VERSION "MUR_Dash_CAN_v1.0"

NS_ :

BS_:

BU_: DASH SCREEN

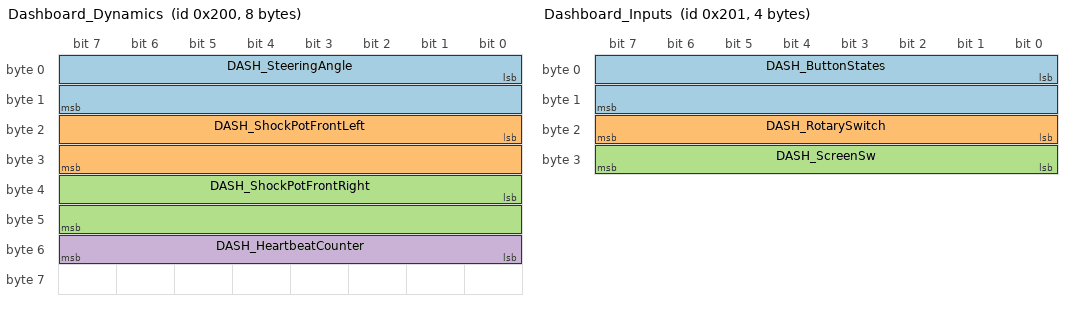
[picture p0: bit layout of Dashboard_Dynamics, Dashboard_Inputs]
BO_ 512 Dashboard_Dynamics: 8 DASH
 SG_ DASH_SteeringAngle : 0|16@1- (0.1,0) [-1800|1800] "deg" SCREEN
 SG_ DASH_ShockPotFrontLeft : 16|16@1+ (0.1,0) [0|500] "mm" SCREEN
 SG_ DASH_ShockPotFrontRight : 32|16@1+ (0.1,0) [0|500] "mm" SCREEN
 SG_ DASH_HeartbeatCounter : 48|8@1+ (1,0) [0|255] "" SCREEN

BO_ 513 Dashboard_Inputs: 4 DASH
 SG_ DASH_ButtonStates : 0|16@1+ (1,0) [0|65535] "" SCREEN
 SG_ DASH_RotarySwitch : 16|8@1+ (1,0) [0|15] "" SCREEN
 SG_ DASH_ScreenSw : 24|8@1+ (1,0) [0|255] "" SCREEN

BO_ 514 Dashboard_Environment: 4 DASH
 SG_ DASH_WindSpeed : 0|16@1+ (0.1,0) [0|6553.5] "m/s" SCREEN

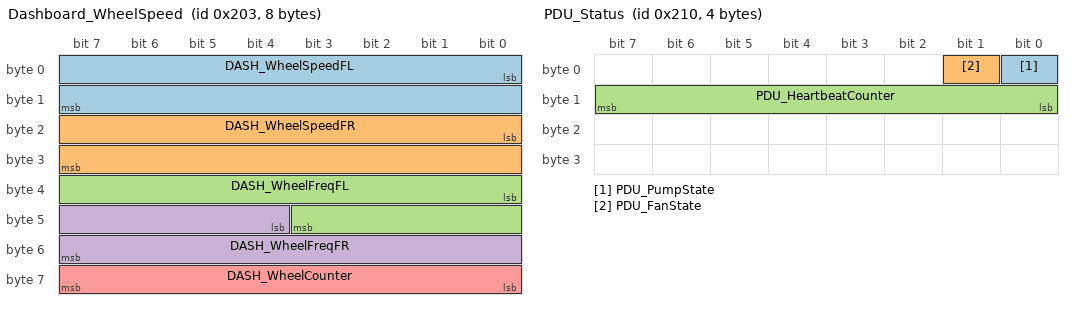
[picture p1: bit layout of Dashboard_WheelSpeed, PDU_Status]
BO_ 515 Dashboard_WheelSpeed: 8 DASH
 SG_ DASH_WheelSpeedFL : 0|16@1+ (0.1,0) [0|6553.4] "rpm" SCREEN
 SG_ DASH_WheelSpeedFR : 16|16@1+ (0.1,0) [0|6553.4] "rpm" SCREEN
 SG_ DASH_WheelFreqFL : 32|12@1+ (1,0) [0|4095] "Hz" SCREEN
 SG_ DASH_WheelFreqFR : 44|12@1+ (1,0) [0|4095] "Hz" SCREEN
 SG_ DASH_WheelCounter : 56|8@1+ (1,0) [0|255] "" SCREEN

BO_ 528 PDU_Status: 4 DASH
 SG_ PDU_PumpState : 0|1@1+ (1,0) [0|1] "" SCREEN
 SG_ PDU_FanState : 1|1@1+ (1,0) [0|1] "" SCREEN
 SG_ PDU_HeartbeatCounter : 8|8@1+ (1,0) [0|255] "" SCREEN

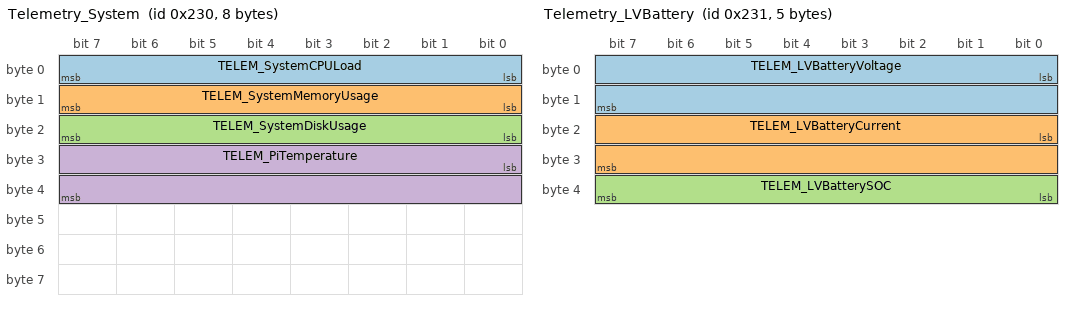
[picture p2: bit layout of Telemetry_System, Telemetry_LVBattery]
BO_ 560 Telemetry_System: 8 DASH
 SG_ TELEM_SystemCPULoad : 0|8@1+ (1,0) [0|100] "%" SCREEN
 SG_ TELEM_SystemMemoryUsage : 8|8@1+ (1,0) [0|100] "%" SCREEN
 SG_ TELEM_SystemDiskUsage : 16|8@1+ (1,0) [0|100] "%" SCREEN
 SG_ TELEM_PiTemperature : 24|16@1- (0.1,0) [-3276.8|3276.7] "degC" SCREEN

BO_ 561 Telemetry_LVBattery: 5 DASH
 SG_ TELEM_LVBatteryVoltage : 0|16@1+ (0.01,0) [0|655.35] "V" SCREEN
 SG_ TELEM_LVBatteryCurrent : 16|16@1- (0.1,0) [-3276.8|3276.7] "A" SCREEN
 SG_ TELEM_LVBatterySOC : 32|8@1+ (1,0) [0|100] "%" SCREEN

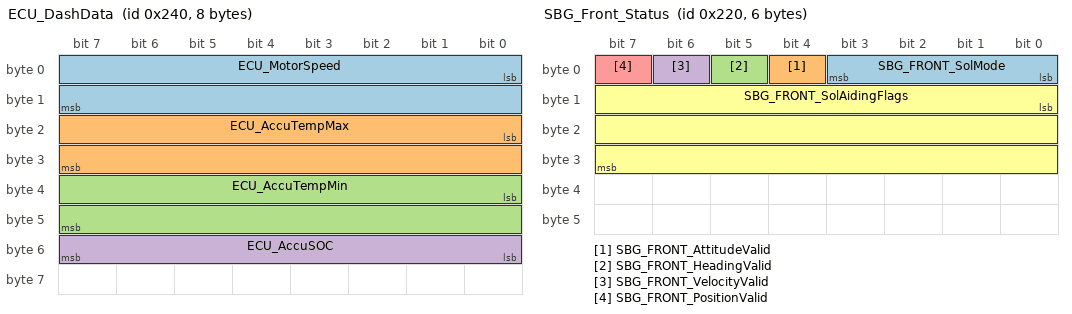
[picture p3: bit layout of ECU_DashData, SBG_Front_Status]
BO_ 576 ECU_DashData: 8 DASH
 SG_ ECU_MotorSpeed : 0|16@1+ (1,0) [0|10000] "rpm" SCREEN
 SG_ ECU_AccuTempMax : 16|16@1- (0.1,0) [-3276.8|3276.7] "degC" SCREEN
 SG_ ECU_AccuTempMin : 32|16@1- (0.1,0) [-3276.8|3276.7] "degC" SCREEN
 SG_ ECU_AccuSOC : 48|8@1+ (1,0) [0|100] "%" SCREEN

BO_ 544 SBG_Front_Status: 6 DASH
 SG_ SBG_FRONT_SolMode : 0|4@1+ (1,0) [0|15] "" SCREEN
 SG_ SBG_FRONT_AttitudeValid : 4|1@1+ (1,0) [0|1] "" SCREEN
 SG_ SBG_FRONT_HeadingValid : 5|1@1+ (1,0) [0|1] "" SCREEN
 SG_ SBG_FRONT_VelocityValid : 6|1@1+ (1,0) [0|1] "" SCREEN
 SG_ SBG_FRONT_PositionValid : 7|1@1+ (1,0) [0|1] "" SCREEN
 SG_ SBG_FRONT_SolAidingFlags : 8|24@1+ (1,0) [0|16777215] "" SCREEN

BO_ 545 SBG_Front_Utc: 8 DASH
 SG_ SBG_FRONT_TimeStamp : 0|32@1+ (1,0) [0|4294967295] "us" SCREEN
 SG_ SBG_FRONT_GpsTow : 32|32@1+ (1,0) [0|4294967295] "ms" SCREEN

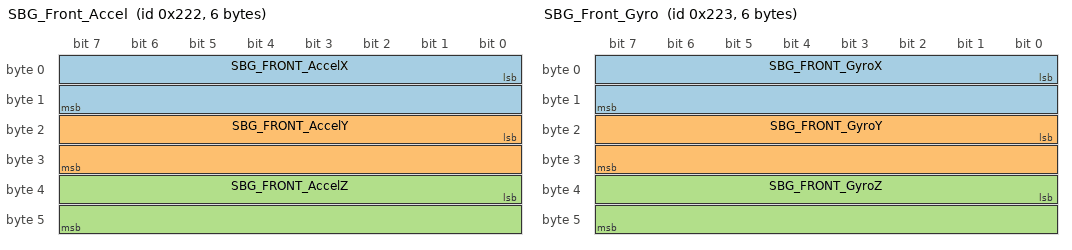
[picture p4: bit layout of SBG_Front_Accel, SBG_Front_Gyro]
BO_ 546 SBG_Front_Accel: 6 DASH
 SG_ SBG_FRONT_AccelX : 0|16@1- (0.01,0) [-327.68|327.67] "m/s^2" SCREEN
 SG_ SBG_FRONT_AccelY : 16|16@1- (0.01,0) [-327.68|327.67] "m/s^2" SCREEN
 SG_ SBG_FRONT_AccelZ : 32|16@1- (0.01,0) [-327.68|327.67] "m/s^2" SCREEN

BO_ 547 SBG_Front_Gyro: 6 DASH
 SG_ SBG_FRONT_GyroX : 0|16@1- (0.001,0) [-32.768|32.767] "rad/s" SCREEN
 SG_ SBG_FRONT_GyroY : 16|16@1- (0.001,0) [-32.768|32.767] "rad/s" SCREEN
 SG_ SBG_FRONT_GyroZ : 32|16@1- (0.001,0) [-32.768|32.767] "rad/s" SCREEN

BO_ 548 SBG_Front_EkfPos: 8 DASH
 SG_ SBG_FRONT_Latitude : 0|32@1- (1E-007,0) [-90|90] "deg" SCREEN
 SG_ SBG_FRONT_Longitude : 32|32@1- (1E-007,0) [-180|180] "deg" SCREEN

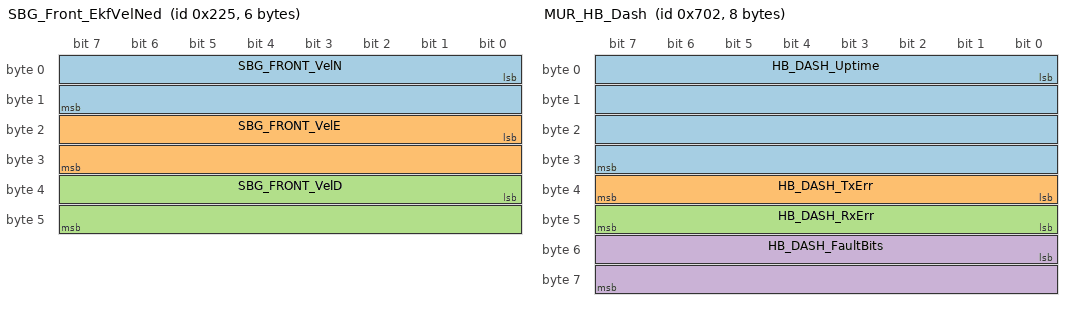
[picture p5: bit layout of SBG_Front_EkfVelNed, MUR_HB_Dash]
BO_ 549 SBG_Front_EkfVelNed: 6 DASH
 SG_ SBG_FRONT_VelN : 0|16@1- (0.01,0) [-327.68|327.67] "m/s" SCREEN
 SG_ SBG_FRONT_VelE : 16|16@1- (0.01,0) [-327.68|327.67] "m/s" SCREEN
 SG_ SBG_FRONT_VelD : 32|16@1- (0.01,0) [-327.68|327.67] "m/s" SCREEN

BO_ 1794 MUR_HB_Dash: 8 DASH
 SG_ HB_DASH_Uptime : 0|32@1+ (1,0) [0|4294967295] "s" SCREEN
 SG_ HB_DASH_TxErr : 32|8@1+ (1,0) [0|255] "" SCREEN
 SG_ HB_DASH_RxErr : 40|8@1+ (1,0) [0|255] "" SCREEN
 SG_ HB_DASH_FaultBits : 48|16@1+ (1,0) [0|65535] "" SCREEN

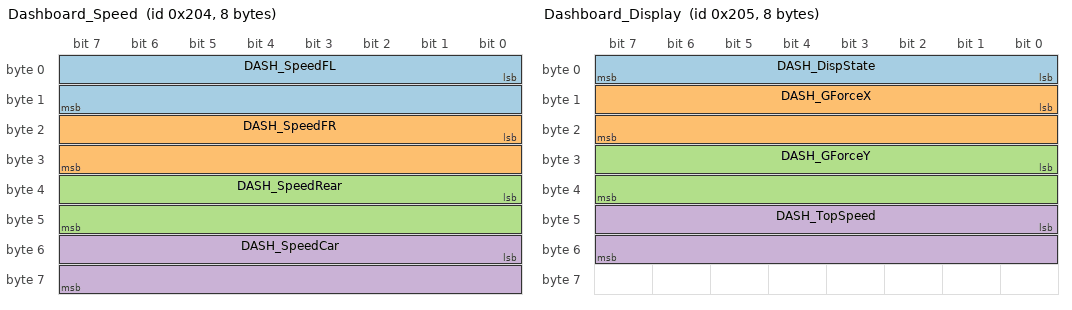
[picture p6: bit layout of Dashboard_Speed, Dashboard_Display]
BO_ 516 Dashboard_Speed: 8 DASH
 SG_ DASH_SpeedFL : 0|16@1+ (0.1,0) [0|6553.4] "km/h" SCREEN
 SG_ DASH_SpeedFR : 16|16@1+ (0.1,0) [0|6553.4] "km/h" SCREEN
 SG_ DASH_SpeedRear : 32|16@1+ (0.1,0) [0|6553.4] "km/h" SCREEN
 SG_ DASH_SpeedCar : 48|16@1+ (0.1,0) [0|6553.4] "km/h" SCREEN

BO_ 517 Dashboard_Display: 8 DASH
 SG_ DASH_DispState : 0|8@1+ (1,0) [0|9] "" SCREEN
 SG_ DASH_GForceX : 8|16@1- (0.01,0) [-327.67|327.66] "g" SCREEN
 SG_ DASH_GForceY : 24|16@1- (0.01,0) [-327.67|327.66] "g" SCREEN
 SG_ DASH_TopSpeed : 40|16@1+ (0.1,0) [0|6553.4] "km/h" SCREEN

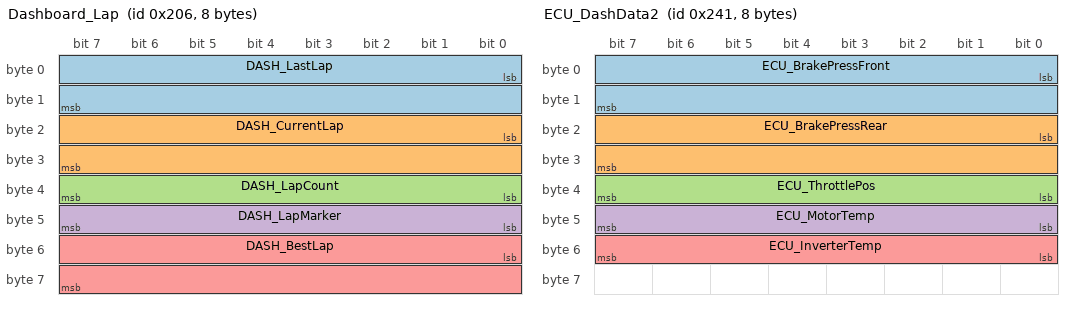
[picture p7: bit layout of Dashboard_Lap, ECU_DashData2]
BO_ 518 Dashboard_Lap: 8 DASH
 SG_ DASH_LastLap : 0|16@1+ (0.01,0) [0|655.34] "s" SCREEN
 SG_ DASH_CurrentLap : 16|16@1+ (0.01,0) [0|655.34] "s" SCREEN
 SG_ DASH_LapCount : 32|8@1+ (1,0) [0|255] "" SCREEN
 SG_ DASH_LapMarker : 40|8@1+ (1,0) [0|1] "" SCREEN
 SG_ DASH_BestLap : 48|16@1+ (0.01,0) [0|655.34] "s" SCREEN

BO_ 577 ECU_DashData2: 8 DASH
 SG_ ECU_BrakePressFront : 0|16@1+ (0.1,0) [0|2000] "psi" SCREEN
 SG_ ECU_BrakePressRear : 16|16@1+ (0.1,0) [0|2000] "psi" SCREEN
 SG_ ECU_ThrottlePos : 32|8@1+ (1,0) [0|100] "%" SCREEN
 SG_ ECU_MotorTemp : 40|8@1+ (1,-40) [-40|214] "degC" SCREEN
 SG_ ECU_InverterTemp : 48|8@1+ (1,-40) [-40|214] "degC" SCREEN

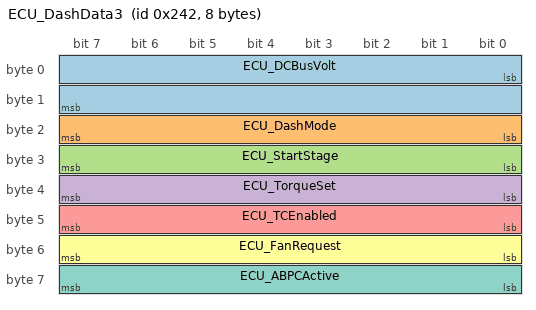
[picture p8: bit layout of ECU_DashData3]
BO_ 578 ECU_DashData3: 8 DASH
 SG_ ECU_DCBusVolt : 0|16@1+ (0.1,0) [0|500] "V" SCREEN
 SG_ ECU_DashMode : 16|8@1+ (1,0) [0|5] "" SCREEN
 SG_ ECU_StartStage : 24|8@1+ (1,0) [0|4] "" SCREEN
 SG_ ECU_TorqueSet : 32|8@1+ (1,0) [0|254] "Nm" SCREEN
 SG_ ECU_TCEnabled : 40|8@1+ (1,0) [0|1] "" SCREEN
 SG_ ECU_FanRequest : 48|8@1+ (1,0) [0|1] "" SCREEN
 SG_ ECU_ABPCActive : 56|8@1+ (1,0) [0|1] "" SCREEN

BO_ 579 ECU_DashSOC: 2 DASH
 SG_ ECU_AccuSOCMin : 0|16@1+ (0.1,0) [0|100] "%" SCREEN

BO_ 519 Dashboard_MaxSpeed: 4 DASH
 SG_ DASH_MaxSpeedFL : 0|16@1+ (0.1,0) [0|6553.4] "km/h" SCREEN
 SG_ DASH_MaxSpeedFR : 16|16@1+ (0.1,0) [0|6553.4] "km/h" SCREEN

BO_ 768 Screen_Switches: 8 SCREEN
 SG_ SCREEN_Switches : 0|8@1+ (1,0) [0|255] "" DASH

CM_ "MUR_Dash_CAN_v1.0: NOTE - IDs 512, 513, 514, 515, 516, 518, 544-549 (front SBG), 576, 577, 578 and 1794 intentionally mirror the definitions in the Sensor/Telemetry CAN DBC. Ensure bus separation is maintained during combined logging to prevent collisions.";
CM_ BU_ DASH "Dashboard Sensor Node - acts as gateway, forwarding CAN frames to the display.";
CM_ BU_ SCREEN "CANchecked MFD28 Gen2 display (2026-10) - sole receiver on this physical bus. Set it to 1000 kbit/s (Setup > Can Bus > Can Speed; it also does 125/250/500) to match the dashboard node, and CanTerm on: it is one end of a two-node bus, the dashboard board is the other. It reads this DBC through CANchecked DSS (TRI Editor > import DBC), where each signal becomes a sensor with a 15-character name limit. It also transmits: Can Switch ON, sending Screen_Switches (0x300) for the dashboard node to act on and relay; Custom Can Frames off, nothing listens for them. It shows any value it is sent, so the invalid sentinels documented per signal display as numbers - handle them with DSS warning limits until the firmware has a validity scheme.";
CM_ BO_ 512 "Dashboard steering/suspension + heartbeat. Transmit rate 100 Hz (FAST).";
CM_ SG_ 512 DASH_SteeringAngle "Signed to allow left/right steering deflection.";
CM_ BO_ 513 "Dashboard driver button states + rotary mode switch. Transmit rate 20 Hz.";
CM_ SG_ 513 DASH_ButtonStates "Bit-per-button: bit i = the dashboard's din-gpios[i], debounced, 1 = pressed. Per the team's pinout (2026-11-14): bit 2 = ready-to-drive (DIN[2], PC0), bit 4 = torque down (DIN[4], PA3), bit 5 = torque up (DIN[5], PA4), bit 6 = fans on/off (DIN[6], PA5), bit 7 = drive mode (DIN[7], PA7). Bits 3 and 8 are the wheel-speed encoder DINs, always 0 here. main_compute's MC_DASH_BTN_* constants must match.";
CM_ SG_ 513 DASH_RotarySwitch "Rotary switch position index (0-15). ASSUMPTION - confirm number of switch positions.";
CM_ SG_ 513 DASH_ScreenSw "The screen's CAN switches, echoed back to it: the same byte the dashboard relays to the ECU on Telemetry CAN (bits 0-6 = CAN switches 1-7, bit 7 = screen heard within 500 ms).";
CM_ BO_ 514 "Dashboard wind speed sensor. Transmit rate 10 Hz (MEDIUM).";
CM_ BO_ 515 "MUR ADDITION (PROVISIONAL): front wheel speeds from the two encoder DINs on the dashboard node (DIN[3] PC13 = FL, DIN[8] PC5 = FR), measured by EXTI edge timing (firmware/lib/dash/dash_wheel). Transmit rate 100 Hz (FAST).";
CM_ SG_ 515 DASH_WheelSpeedFL "Wheel rpm = pulse frequency x 60 / pulses-per-rev. 0xFFFF (6553.5) = invalid: encoder pulses-per-rev not calibrated yet (TODO(calib)) - read DASH_WheelFreqFL instead. 0 after ~0.5 s with no pulse.";
CM_ SG_ 515 DASH_WheelSpeedFR "See DASH_WheelSpeedFL.";
CM_ SG_ 515 DASH_WheelFreqFL "Raw encoder pulse frequency, independent of any calibration - the bench/sanity view. Saturates at 4095 (= at least 4095 Hz).";
CM_ SG_ 515 DASH_WheelFreqFR "See DASH_WheelFreqFL.";
CM_ SG_ 515 DASH_WheelCounter "Increments every frame; a frozen counter means a stalled node.";
CM_ BO_ 528 "PDU pump/fan on-off state + heartbeat. Transmit rate 10 Hz (SLOW). Byte 2 reserved for future PDU_FanSpeed once speed control is implemented (see Telemetry_CAN.md).";
CM_ BO_ 560 "Telemetry Pi system health (CPU/mem/disk/temp), broadcast for dashboard display. Transmit rate 5 Hz.";
CM_ BO_ 561 "Telemetry Pi: the LV battery with the lower state of charge. The Pi reads both Allion AL1220-BT batteries over Bluetooth (bms_telemetry) and sends this frame for whichever fresh battery reports the lower SoC; voltage and current are that same battery's. A battery is fresh if it reported in the last 10 s. With no fresh battery the frame is still sent, with every signal at its invalid value. No frame at all means the Pi or its bridge is down. Transmit rate 2 Hz (SLOW).";
CM_ SG_ 561 TELEM_LVBatteryVoltage "LV battery terminal voltage, from the battery's own BMS. Raw 0xFFFF = invalid (no fresh battery). Battery reports mV: assumed from its readings, not yet checked against a meter.";
CM_ SG_ 561 TELEM_LVBatteryCurrent "LV battery current, from the battery's own BMS; positive = discharging, negative = charging (the battery's own sign). Raw 0x7FFF = invalid (no fresh battery). Battery reports mA: assumed, not yet checked against a clamp meter.";
CM_ SG_ 561 TELEM_LVBatterySOC "State of charge of the lower of the LV batteries, whole percent, rounded down from the battery BMS's 0.01 % value. Raw 0xFF = invalid (no fresh battery). Only as good as the battery's own SoC estimate.";
CM_ BO_ 576 "MUR ADDITION (PROVISIONAL): the ECU's Telemetry CAN ECU_DashData, forwarded unchanged by the dashboard. Transmit rate 10 Hz (the ECU's best-effort thread). 8 bytes from day one; byte 7 is still reserved: add new display signals there, byte-aligned and 8 or 16 bits wide so the MFD28's DSS import reads them cleanly, and never move, resize or rescale an existing one. The dashboard forwards this frame to Dash CAN byte-for-byte, so it must stay identical in mur_dashboard_can.dbc (scripts/validate.py checks); adding a signal then needs no dashboard firmware change.";
CM_ SG_ 576 ECU_MotorSpeed "Motor speed magnitude in rpm, from the inverter's INV_MotorPosition on Tractive CAN, clipped to 0-10000 by the ECU; no direction. 0xFFFF = invalid: the ECU has not heard the inverter yet, or has lost it (comms timeout).";
CM_ SG_ 576 ECU_AccuTempMax "Canonical car accumulator maximum, converted by ECU using voltage recovery and Table 5. Prefer complete fresh sweeps; if no sweep frames are fresh, use a fresh mapped summary maximum (1 degC input resolution). Partial or invalid live sweeps prevent fallback. 0x7FFF is invalid. Identical ECU_DashData bytes reach TTCS on Control CAN and screen on Telemetry/Dash CAN.";
CM_ SG_ 576 ECU_AccuTempMin "Corrected minimum from complete fresh sensor sweeps. 0x7FFF is invalid, including during summary-maximum fallback; summary supplies no minimum.";
CM_ SG_ 576 ECU_AccuSOC "Accumulator SOC in whole percent. ECU firmware with ECU_DashSOC derives this from TTCS_ModelSOCMin; older firmware uses ENNOID summary SOC. 0xFF = unavailable.";
CM_ BO_ 579 "Driver display SOC at 10 Hz. ECU publishes on Telemetry CAN; dashboard forwards the same bytes to Dash CAN.";
CM_ SG_ 579 ECU_AccuSOCMin "Lowest TTCS model group SOC at 0.1 percent per count. Raw 0xFFFF (6553.5 percent) means TTCS SOC is invalid or stale. Display only.";
CM_ BO_ 544 "MUR ADDITION (PROVISIONAL): the front SBG Ellipse-D's Telemetry CAN frame, forwarded unchanged by the dashboard (rear unit not forwarded). Layout, names and rate are vendor/SBG_Ellipse.dbc's, and must stay identical to it (scripts/validate.py FORWARDED). SBG_ECAN_MSG_STATUS_03 (SBG default ID 0x102), front unit. Bytes 4-5 are HEAVE_STATUS (ship-motion status, meaningless on a car) - left undefined.";
CM_ BO_ 545 "MUR ADDITION (PROVISIONAL): the front SBG Ellipse-D's Telemetry CAN frame, forwarded unchanged by the dashboard (rear unit not forwarded). Layout, names and rate are vendor/SBG_Ellipse.dbc's, and must stay identical to it (scripts/validate.py FORWARDED). SBG_ECAN_MSG_UTC_0 (SBG default ID 0x110), front unit. TimeStamp is time since the unit powered up; GpsTow is GPS time of week - use it to line up the two units and other logs.";
CM_ BO_ 546 "MUR ADDITION (PROVISIONAL): the front SBG Ellipse-D's Telemetry CAN frame, forwarded unchanged by the dashboard (rear unit not forwarded). Layout, names and rate are vendor/SBG_Ellipse.dbc's, and must stay identical to it (scripts/validate.py FORWARDED). SBG_ECAN_MSG_IMU_ACCEL (SBG default ID 0x121), front unit. Calibrated accelerometer, sensor body frame.";
CM_ BO_ 547 "MUR ADDITION (PROVISIONAL): the front SBG Ellipse-D's Telemetry CAN frame, forwarded unchanged by the dashboard (rear unit not forwarded). Layout, names and rate are vendor/SBG_Ellipse.dbc's, and must stay identical to it (scripts/validate.py FORWARDED). SBG_ECAN_MSG_IMU_GYRO (SBG default ID 0x122), front unit. Calibrated gyro, sensor body frame.";
CM_ BO_ 548 "MUR ADDITION (PROVISIONAL): the front SBG Ellipse-D's Telemetry CAN frame, forwarded unchanged by the dashboard (rear unit not forwarded). Layout, names and rate are vendor/SBG_Ellipse.dbc's, and must stay identical to it (scripts/validate.py FORWARDED). SBG_ECAN_MSG_EKF_POS (SBG default ID 0x134), front unit. WGS84 latitude/longitude from the INS solution; invalid until SolMode = NavPosition.";
CM_ BO_ 549 "MUR ADDITION (PROVISIONAL): the front SBG Ellipse-D's Telemetry CAN frame, forwarded unchanged by the dashboard (rear unit not forwarded). Layout, names and rate are vendor/SBG_Ellipse.dbc's, and must stay identical to it (scripts/validate.py FORWARDED). SBG_ECAN_MSG_EKF_VEL_NED (SBG default ID 0x137), front unit. INS velocity in the North/East/Down frame, not the car frame.";
CM_ SG_ 544 SBG_FRONT_SolMode "SOLUTION_STATUS bits 0-3: EKF solution mode. Nothing but NavPosition means position/velocity are trustworthy.";
CM_ SG_ 544 SBG_FRONT_SolAidingFlags "SOLUTION_STATUS bits 8-31: aiding-used flags, SBG_ECOM_SOL_* bit N maps to bit N-8 here (e.g. bit 11 GPS1_POS_USED -> bit 3, bit 27 ALIGN_VALID -> bit 19). See sbgECom doc/binaryMessages.md SOLUTION_STATUS.";
CM_ BO_ 516 "MUR ADDITION (PROVISIONAL): wheel speeds in km/h for the driver's screen, computed on the dashboard node (firmware/lib/dash/dash_speed) and sent with identical bytes on Telemetry and Dash CAN (scripts/validate.py FORWARDED keeps the two definitions the same). Transmit rate 20 Hz. Same equations as mur-embedded's tools/bench/mur_can.py: 0.0766 km/h per wheel rpm (a 16 in tyre, assumed from the factor, not measured on the car).";
CM_ SG_ 516 DASH_SpeedFL "Front left wheel km/h = DASH_WheelSpeedFL x 0.0766. 0xFFFF (6553.5) = invalid whenever DASH_WheelSpeedFL is.";
CM_ SG_ 516 DASH_SpeedFR "Front right wheel km/h; see DASH_SpeedFL.";
CM_ SG_ 516 DASH_SpeedRear "Rear wheel km/h from motor speed, there being no rear wheel sensor: ECU_MotorSpeed / 4.777 (the final drive ratio as given by the team 2026-11-01) x 0.0766. The diff makes it the average of the two rear wheels, so it reads a little off from either one in a corner. 0xFFFF (6553.5) = invalid: ECU_MotorSpeed is invalid, or the dashboard has had no ECU_DashData for 500 ms.";
CM_ SG_ 516 DASH_SpeedCar "MUR ADDITION (PROVISIONAL): one car speed for the screen's speed readouts (the lap-timing and autocross pages): the mean of DASH_SpeedFL and DASH_SpeedFR, or whichever one is valid. The fronts are undriven, so wheelspin does not inflate it, unlike DASH_SpeedRear. 0xFFFF (6553.5) = invalid: neither front speed is valid.";
CM_ BO_ 518 "MUR ADDITION (PROVISIONAL): lap timing for the driver's screen, computed on the dashboard node (firmware/lib/dash/dash_lap) from presses of the driver's ready-to-drive (RTD) button, and sent with identical bytes on Telemetry and Dash CAN (scripts/validate.py FORWARDED). Transmit rate 10 Hz. Bytes 6-7 carry the best lap. Manual timing with no GPS (maintainer direction 2026-11-19): while the car is ready to drive (ECU_DashData3 ECU_StartStage 4, heard within 500 ms), each press of the RTD button (a rising edge of Dashboard_Inputs DASH_ButtonStates bit 2) is a lap marker. The first press starts the lap clock; each later press ends the current lap and starts the next, unless it comes less than 2 s after the lap started, which is ignored so a double press cannot record a near-zero lap. Presses while the car is not ready to drive are ignored, including the press that arms ready-to-drive. Entering ready-to-drive clears the lap times and count. Every press goes through the same 30 ms debounce, so a lap time is as good as the driver's timing of the press. Bench-unverified. Lives in RAM: a dashboard reset also clears it.";
CM_ SG_ 518 DASH_LastLap "Time of the last completed lap. 0xFFFF (655.35) = none yet: no lap completed since the car last entered ready-to-drive (or since the dashboard started). A lap longer than 655.34 s reads 655.34.";
CM_ SG_ 518 DASH_CurrentLap "Time since the current lap started. 0xFFFF (655.35) = lap timing not started: no RTD-button lap press since the car last entered ready-to-drive. Saturates at 655.34.";
CM_ SG_ 518 DASH_LapCount "Laps completed since the car last entered ready-to-drive; wraps at 255.";
CM_ SG_ 518 DASH_BestLap "Fastest lap completed since the car last entered ready-to-drive. 0xFFFF (655.35) = none yet.";
CM_ SG_ 518 DASH_LapMarker "1 = lap timing is running: the RTD button has been pressed as a lap marker since the car last entered ready-to-drive. 0 = not started. Until 2026-11-19 this meant a GPS start/finish marker was set; the GPS lap timer has been removed.";
CM_ BO_ 517 "MUR ADDITION (PROVISIONAL): display-only values the dashboard node works out for the screen (Dash CAN only, never logged). Transmit rate 20 Hz. Byte 7 reserved.";
CM_ SG_ 517 DASH_DispState "The page the screen should show. 0 = startup or unknown: the tractive system is on but the car is not yet ready to drive (ECU_DashData3 ECU_StartStage 1-3: the screen's startup page, maintainer direction 2026-11-19), or no ECU_DashData3 for 500 ms. Otherwise ECU_DashData3's ECU_DashMode (1 Accel, 2 Skidpad, 3 AutoX, 4 Endurance, 5 Custom), including while the tractive system is off (ECU_StartStage 0) so the driver can pick a mode, except that while ECU_ABPCActive is 1 it alternates every 100 ms between that mode and 9 (the solid-blue ABPC page; 9 to match the screen's page number, the team's choice 2026-11-14), flashing the screen to tell the driver the APPS/brake plausibility check is cutting torque.";
CM_ SG_ 517 DASH_GForceX "Front SBG longitudinal acceleration in g (SBG_FRONT_AccelX / 9.80665), rounded to 0.01 g. Sensor body frame, so its sign follows how the unit is mounted: check it on the car (positive should be accelerating). 0x7FFF (327.67) = invalid: no SBG_Front_Accel for 200 ms.";
CM_ SG_ 517 DASH_GForceY "Front SBG lateral acceleration in g (SBG_FRONT_AccelY / 9.80665); see DASH_GForceX.";
CM_ SG_ 517 DASH_TopSpeed "Highest car speed since boot or the last drive-mode change, for the accel page: the highest Dashboard_Speed DASH_SpeedCar (the front wheels, so wheelspin does not inflate it). 0 until a valid speed has been seen.";
CM_ BO_ 519 "MUR ADDITION (PROVISIONAL): the highest front wheel speeds of the current run, for the driver's screen (Dash CAN only, never logged; maintainer direction 2026-11-19), computed on the dashboard node (firmware/lib/dash/dash_max_speed) from Dashboard_Speed's DASH_SpeedFL and DASH_SpeedFR. Transmit rate 10 Hz. A run ends when the car stops: DASH_SpeedCar below 1.0 km/h for 1 s. Both maxima then hold, so they can be read while stationary, and both reset to 0 when the car next moves off (DASH_SpeedCar above 3.0 km/h); that first moving sample starts the new maxima. The 1.0 and 3.0 km/h and 1 s thresholds are provisional, not tuned on the car. Separate from Dashboard_Display DASH_TopSpeed, which keeps its own reset rule.";
CM_ SG_ 519 DASH_MaxSpeedFL "Highest valid DASH_SpeedFL this run, km/h. 0 until a valid speed has been seen since the last reset. Never the 0xFFFF invalid value.";
CM_ SG_ 519 DASH_MaxSpeedFR "Highest valid DASH_SpeedFR this run; see DASH_MaxSpeedFL.";
CM_ BO_ 578 "MUR ADDITION (PROVISIONAL): the driver-interface state the ECU owns, for the screen: drive mode, the torque setting, traction control and fan requests, the startup stage and the APPS/brake plausibility (ABPC) state, plus the inverter's DC bus voltage for the precharge bar. Transmit rate 10 Hz (the ECU's best-effort thread). The dashboard forwards it to Dash CAN byte-for-byte, so it must stay identical in mur_dashboard_can.dbc (scripts/validate.py FORWARDED); every signal is byte-aligned and 8 or 16 bits wide for the MFD28. The mode selects a torque limit and that limit is applied (see ECU_TorqueSet). TC and the fan request are still DISPLAY ONLY: there is no traction control, and PDU_Control is unchanged.";
CM_ SG_ 578 ECU_DCBusVolt "Inverter DC bus voltage (INV_DCBusVoltage), as the ECU last received it on Tractive CAN. 0xFFFF (6553.5) = invalid: the ECU has not heard the inverter yet, or has lost it (comms timeout).";
CM_ SG_ 578 ECU_DashMode "Driver-selected mode, 1-5 (see VAL_). Cycled 1-2-3-4-5-1 by the dash mode button (Dashboard_Inputs DASH_ButtonStates bit 7); boots in Endurance. The ABPC page is not a mode: see ECU_ABPCActive. Selects the torque limit: each preset its own, Custom the driver's (see ECU_TorqueSet, including the wait for the throttle to lift after a change).";
CM_ SG_ 578 ECU_StartStage "Where the driver is in the ready-to-drive sequence (see VAL_). 0 = not available: tractive system off, or the car in Init/Fault/Shutdown. 1 = wait: tractive system on, the inverter fault-clear and 5 s startup wait still running. 2 = press the brake: Standby, the wait over, brake below the ready threshold. 3 = press the start button: as 2 with the brake above it. 4 = ready to drive (ReadyToDrive or Driving).";
CM_ SG_ 578 ECU_TorqueSet "The driver torque limit IN FORCE, whole Nm, APPLIED by the ECU (2026-11-14): commanded torque is capped at the lowest of this, the ECU power map (ECU_PowerMapSet) and the ECU's 160 Nm ceiling, with the pedal scaled to that cap so full pedal reaches it. Each preset mode has its own limit set in firmware: Accel 140, Skidpad 80, AutoX 120, Endurance 120 Nm (team values, 2026-11-14). In Custom the torque-down/up buttons - the screen's CAN switches 1 and 2, or the physical dash buttons (DASH_ButtonStates bits 4 and 5) - step it by 5 Nm within 10-160 Nm, taking effect at once; they do nothing in the presets, and Custom keeps its value while another mode is selected. After a MODE CHANGE the old mode's limit stays in force until the driver is off the throttle (deadzone, pedal stream lost, or not ReadyToDrive/Driving), so this shows the new mode's limit only once it has taken over. 120 Nm at power-up (Endurance). RAM only. If the dash goes quiet the ECU keeps the last selection.";
CM_ SG_ 578 ECU_TCEnabled "1 = traction control switched on by the driver (screen CAN switch 3, toggles on each change). Boots 0. There is no traction control in the firmware yet: this is the setting only.";
CM_ SG_ 578 ECU_FanRequest "1 = the driver interface wants the cooling fans running: always 1 while ECU_TSActive, otherwise the dash fan button's toggle (DASH_ButtonStates bit 6; boots 0). NOT SENT TO THE PDM yet - PDU_Control still requests Fan2 in every state (switching Fan2 off would also stop the pump and HighCurrent, see docs/PDM-Docs.md). PDU_Status shows the fans' actual state.";
CM_ SG_ 578 ECU_ABPCActive "1 = the APPS/brake pedal plausibility check is cutting torque: the ECU's TempBlock latch (brake above the ready threshold with more than 25 % throttle, held until throttle drops below 5 %) while ReadyToDrive or Driving. The dashboard flashes the screen's ABPC page (Dashboard_Display DASH_DispState = 9) while this is 1.";
CM_ BO_ 768 "MUR ADDITION (PROVISIONAL): the MFD28's custom Can frame 1 (DSS: Other settings > Can Transmit), the one frame the screen transmits. ID, layout and rate match the screen's own DSS export (CANchecked_Custom_Transmit.dbc, 2026-11-14): 0x300, 8 bytes, byte 0 bits 0-7 = CAN switches 1-8 (Data Type 'Can switches 1-8'), 20 Hz. Not yet seen on the car's bus. The dashboard reads byte 0 from a frame of any length, in case the screen sends fewer bytes than the DBC says, and relays it to the ECU as Dashboard_Inputs DASH_ScreenSw.";
CM_ SG_ 768 SCREEN_Switches "Bit n-1 = CAN switch n; only switches 1-7 are used, bit 7 is ignored. Latching (DSS Momentary unticked): a change of a bit is one press. 1 = torque down, 2 = torque up, 3 = traction control. 4 is unused: it set the GPS lap marker until 2026-11-19, and laps are now marked with the RTD button (Dashboard_Lap).";
CM_ BO_ 577 "MUR ADDITION (PROVISIONAL): more driver-display data from the ECU, ECU_DashData being full: brake pressures and throttle from the pedalbox's Pedal_Status, motor and inverter temperatures from the inverter, all on Tractive CAN. Transmit rate 10 Hz (the ECU's best-effort thread). The dashboard forwards it to Dash CAN byte-for-byte, so it must stay identical in mur_dashboard_can.dbc (scripts/validate.py FORWARDED). Byte 7 reserved: add display signals there, byte-aligned and 8 or 16 bits wide, never moving, resizing or rescaling an existing one.";
CM_ SG_ 577 ECU_BrakePressFront "PEDAL_BrakePressure1 (front circuit) as the ECU last received it. 0xFFFF (6553.5) = invalid: the ECU has not heard Pedal_Status yet, or it has timed out or frozen (the ECU's pedal comm_err).";
CM_ SG_ 577 ECU_BrakePressRear "PEDAL_BrakePressure2 (rear circuit); see ECU_BrakePressFront.";
CM_ SG_ 577 ECU_ThrottlePos "Accelerator pedal: the mean of PEDAL_Position1 and PEDAL_Position2, rounded to whole %. Shown even when the two disagree; APPS plausibility is the ECU's fault logic, not the screen's. 0xFF = invalid, as for ECU_BrakePressFront.";
CM_ SG_ 577 ECU_MotorTemp "Motor temperature, whole degC, from the inverter's INV_MotorRawTemp (its motor temperature input). Offset -40: raw 0 = -40 degC, clamped to -40..214. 0xFF (215) = invalid: the ECU has not heard the inverter, has lost it (comms timeout), or the inverter reports its 1381 sensor-fault value.";
CM_ SG_ 577 ECU_InverterTemp "Inverter temperature: the hottest of its three IGBT module temperatures (INV_ModuleA/B/CTemp), whole degC, offset -40, clamped to -40..214. 0xFF (215) = invalid: the ECU has not heard the inverter, or has lost it.";
CM_ BO_ 1794 "MUR ADDITION (PROVISIONAL): 1 Hz dashboard node heartbeat, ID 0x700 + node id (Dashboard = 2). Uptime, CAN error counters, low 16 bits of latched fault mask. Signals node-prefixed for bus-wide uniqueness.";

BA_DEF_ BO_ "GenMsgCycleTime" INT 0 100000;
BA_DEF_ BO_ "GenMsgSendType" ENUM "Cyclic","OnChange","Event";
BA_DEF_ "BusType" STRING ;
BA_DEF_DEF_ "GenMsgCycleTime" 0;
BA_DEF_DEF_ "GenMsgSendType" "Cyclic";
BA_DEF_DEF_ "BusType" "CAN";
BA_ "GenMsgCycleTime" BO_ 512 10;
BA_ "GenMsgCycleTime" BO_ 513 50;
BA_ "GenMsgCycleTime" BO_ 514 100;
BA_ "GenMsgCycleTime" BO_ 515 10;
BA_ "GenMsgCycleTime" BO_ 528 100;
BA_ "GenMsgCycleTime" BO_ 560 200;
BA_ "GenMsgCycleTime" BO_ 561 500;
BA_ "GenMsgCycleTime" BO_ 576 100;
BA_ "GenMsgCycleTime" BO_ 579 100;
BA_ "GenMsgCycleTime" BO_ 544 100;
BA_ "GenMsgCycleTime" BO_ 545 1000;
BA_ "GenMsgCycleTime" BO_ 546 10;
BA_ "GenMsgCycleTime" BO_ 547 10;
BA_ "GenMsgCycleTime" BO_ 548 100;
BA_ "GenMsgCycleTime" BO_ 549 20;
BA_ "GenMsgCycleTime" BO_ 516 50;
BA_ "GenMsgCycleTime" BO_ 577 100;
BA_ "GenMsgCycleTime" BO_ 768 50;
BA_ "GenMsgCycleTime" BO_ 578 100;
BA_ "GenMsgCycleTime" BO_ 518 100;
BA_ "GenMsgCycleTime" BO_ 517 50;
BA_ "GenMsgCycleTime" BO_ 519 100;
BA_ "GenMsgCycleTime" BO_ 1794 1000;

VAL_ 544 SBG_FRONT_SolMode 0 "Uninitialized" 1 "VerticalGyro" 2 "AHRS" 3 "NavVelocityDeprecated" 4 "NavPosition" ;
VAL_ 578 ECU_DashMode 1 "Accel" 2 "Skidpad" 3 "AutoX" 4 "Endurance" 5 "Custom" ;
VAL_ 578 ECU_StartStage 0 "NotAvailable" 1 "Wait" 2 "PressBrake" 3 "PressStart" 4 "ReadyToDrive" ;
VAL_ 517 DASH_DispState 0 "Startup" 1 "Accel" 2 "Skidpad" 3 "AutoX" 4 "Endurance" 5 "Custom" 9 "ABPC" ;
